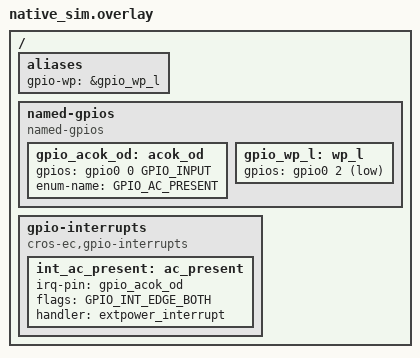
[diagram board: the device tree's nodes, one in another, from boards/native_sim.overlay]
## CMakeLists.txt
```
# Copyright 2025 The ChromiumOS Authors
# Use of this source code is governed by a BSD-style license that can be
# found in the LICENSE file.

cmake_minimum_required(VERSION 3.13.1)
find_package(Zephyr REQUIRED HINTS "${ZEPHYR_BASE}")
project(extpower)

zephyr_include_directories("${CMAKE_CURRENT_SOURCE_DIR}/include")

add_subdirectory(${PLATFORM_EC}/zephyr/test/test_utils test_utils)

target_sources(app PRIVATE
  src/main.c
  src/acok_emul.c
  )

target_sources_ifdef(CONFIG_LINK_TEST_SUITE_EXTPOWER_DEFAULT app
  PRIVATE src/extpower.c
  )

target_sources_ifdef(CONFIG_LINK_TEST_SUITE_EXTPOWER_INIT app
  PRIVATE src/extpower_init.c)
```

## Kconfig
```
# Copyright 2025 The ChromiumOS Authors
# Use of this source code is governed by a BSD-style license that can be
# found in the LICENSE file.

source "Kconfig.zephyr"

config LINK_TEST_SUITE_EXTPOWER_DEFAULT
	bool "Link and test the extpower test suites"
	help
	  Link and test the extpower tests suites, excluding the
	  the init test.

config LINK_TEST_SUITE_EXTPOWER_INIT
	bool "Link and test the extpower init test suite"
	help
	  Link and test the extpower init test suite.

config ACOK_INIT_VALUE
	int "Initial logical value of the AC OK input"
	default 0
	range 0 1
	help
	  This sets the initial logical value of the AC OK input for the
	  extpower tests.
```

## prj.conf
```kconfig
# Copyright 2025 The ChromiumOS Authors
# Use of this source code is governed by a BSD-style license that can be
# found in the LICENSE file.

CONFIG_ZTEST=y

CONFIG_PLATFORM_EC=y
CONFIG_CROS_EC=y
CONFIG_SHIMMED_TASKS=y
CONFIG_PLATFORM_EC_EXTPOWER_GPIO=y

CONFIG_SERIAL=y
CONFIG_SHELL=y
CONFIG_SHELL_BACKEND_DUMMY=y
CONFIG_SHELL_BACKEND_SERIAL=n

CONFIG_AP_POWER_EVENTS_MOCK=y

CONFIG_PLATFORM_EC_HOSTCMD=y

CONFIG_PLATFORM_EC_VBOOT_HASH=n
CONFIG_AP_EVENTS=n
CONFIG_PLATFORM_EC_SWITCH=n
```

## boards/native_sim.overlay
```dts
/* Copyright 2025 The ChromiumOS Authors
 * Use of this source code is governed by a BSD-style license that can be
 * found in the LICENSE file.
 */

#include <board-overlays/native_sim.dts>
#include <dt-bindings/kbd.h>

/ {
	aliases {
		gpio-wp = &gpio_wp_l;
	};

	named-gpios {
		compatible = "named-gpios";

		gpio_acok_od: acok_od {
			gpios = <&gpio0 0 GPIO_INPUT>;
			enum-name = "GPIO_AC_PRESENT";
		};
		gpio_wp_l: wp_l {
			gpios = <&gpio0 2 (GPIO_INPUT | GPIO_ACTIVE_LOW)>;
		};
	};
	gpio-interrupts {
		compatible = "cros-ec,gpio-interrupts";

		int_ac_present: ac_present {
			irq-pin = <&gpio_acok_od>;
			flags = <GPIO_INT_EDGE_BOTH>;
			handler = "extpower_interrupt";
		};
	};
};
```

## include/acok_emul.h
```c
/* Copyright 2025 The ChromiumOS Authors
 * Use of this source code is governed by a BSD-style license that can be
 * found in the LICENSE file.
 */

#ifndef ZEPHYR_TEST_EXTPOWER_INCLUDE_ACOK_EMUL_H_
#define ZEPHYR_TEST_EXTPOWER_INCLUDE_ACOK_EMUL_H_

#include <stdbool.h>

void set_ac(int on, bool wait);

#endif /* ZEPHYR_TEST_EXTPOWER_INCLUDE_ACOK_EMUL_H_ */
```

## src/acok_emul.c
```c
/* Copyright 2025 The ChromiumOS Authors
 * Use of this source code is governed by a BSD-style license that can be
 * found in the LICENSE file.
 */

#include <zephyr/drivers/gpio/gpio_emul.h>

static const struct device *acok_gpio_dev =
	DEVICE_DT_GET(DT_GPIO_CTLR(DT_NODELABEL(gpio_acok_od), gpios));
static const gpio_port_pins_t acok_pin =
	DT_GPIO_PIN(DT_NODELABEL(gpio_acok_od), gpios);

void set_ac(int on, bool wait)
{
	gpio_emul_input_set(acok_gpio_dev, acok_pin, on);

	if (wait) {
		k_msleep(CONFIG_PLATFORM_EC_EXTPOWER_DEBOUNCE_MS * 10);
	}
}

/* This is meant to run prior to the ec_app_main() so that the AC OK
 * GPIO level can be set high or low before the extpower_init() routine
 * runs.
 */
static int acok_asserted_init(void)
{
	set_ac(CONFIG_ACOK_INIT_VALUE, false);

	return 0;
}

SYS_INIT(acok_asserted_init, APPLICATION, 50);
```

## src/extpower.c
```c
/* Copyright 2025 The ChromiumOS Authors
 * Use of this source code is governed by a BSD-style license that can be
 * found in the LICENSE file.
 */

#include "acok_emul.h"
#include "extpower.h"
#include "hooks.h"
#include "host_command.h"
#include "lpc.h"

#include <zephyr/drivers/gpio/gpio_emul.h>
#include <zephyr/ztest.h>

static int ac_hook_count;

static void before_and_after(void *unused)
{
	if (IS_ENABLED(HAS_TASK_HOSTCMD)) {
		host_clear_events(0xFFFFFFFF);
	}
}

static void test_ac_change_hook(void)
{
	ac_hook_count++;
}
DECLARE_HOOK(HOOK_AC_CHANGE, test_ac_change_hook, HOOK_PRIO_DEFAULT);

ZTEST(extpower, test_extpower_gpio)
{
	set_ac(0, true);
	ac_hook_count = 0;

	set_ac(1, true);
	zassert_equal(ac_hook_count, 1);
	zassert_equal(extpower_is_present(), 1);

	if (IS_ENABLED(HAS_TASK_HOSTCMD)) {
		zassert_true(host_is_event_set(EC_HOST_EVENT_AC_CONNECTED));
	}

	set_ac(0, true);
	zassert_equal(ac_hook_count, 2);
	zassert_equal(extpower_is_present(), 0);

	if (IS_ENABLED(HAS_TASK_HOSTCMD)) {
		zassert_true(host_is_event_set(EC_HOST_EVENT_AC_DISCONNECTED));
	}
}

ZTEST(extpower, test_extpower_gpio_debounce)
{
	/* Verify that changes to AC OK that are less than the debounce time
	 * do not generate HOOK or HOSTCMD events.
	 */
	set_ac(0, true);
	ac_hook_count = 0;

	set_ac(1, false);
	k_msleep(CONFIG_PLATFORM_EC_EXTPOWER_DEBOUNCE_MS / 2);
	set_ac(0, true);

	zassert_equal(ac_hook_count, 0);

	if (IS_ENABLED(HAS_TASK_HOSTCMD)) {
		zassert_false(host_is_event_set(EC_HOST_EVENT_AC_CONNECTED));
		zassert_false(host_is_event_set(EC_HOST_EVENT_AC_DISCONNECTED));
	}
}

ZTEST_SUITE(extpower, NULL, NULL, before_and_after, before_and_after, NULL);
```

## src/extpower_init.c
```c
/* Copyright 2025 The ChromiumOS Authors
 * Use of this source code is governed by a BSD-style license that can be
 * found in the LICENSE file.
 */

#include "acok_emul.h"
#include "extpower.h"
#include "hooks.h"
#include "host_command.h"
#include "lpc.h"

#include <zephyr/drivers/gpio/gpio_emul.h>
#include <zephyr/ztest.h>

ZTEST(extpower_init, test_extpower_init)
{
	/* Validate the initial state of the AC OK pin is captured by
	 * the extpower support.
	 */
	zassert_equal(extpower_is_present(), CONFIG_ACOK_INIT_VALUE);
}

ZTEST_SUITE(extpower_init, NULL, NULL, NULL, NULL, NULL);
```
